# STM32H755_CM7 register map
File version: 2.6
CPU: CM7 r0p1, little endian, MPU, FPU, 4 interrupt priority bits
Registers are 32-bit, read-write, reset 0x0 unless marked. A register's access mark holds for its fields unless they carry their own. Offsets are from the block's base; [hi:lo] are bit positions; {n}, {i} and the like mark numbered series; 'fields as' and 'values as' point back to an identical list.

## ADC3_Common — Analog-to-Digital Converter
Base 0x58026300
Same registers: ADC12_Common 0x40022300
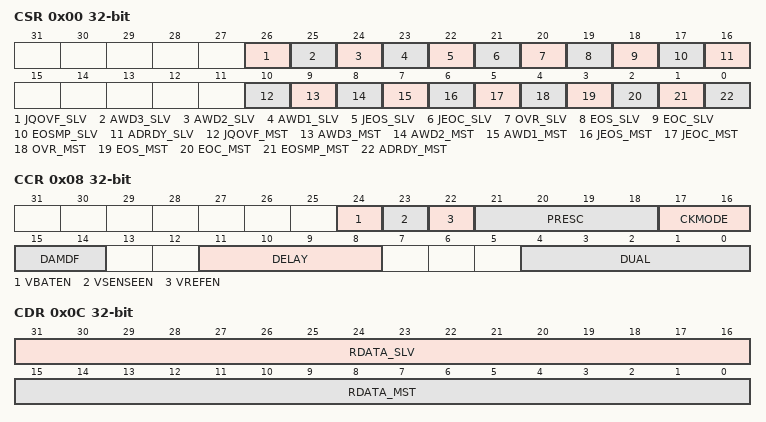
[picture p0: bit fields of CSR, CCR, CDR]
0x00 CSR ro — ADC Common status register
  [26] JQOVF_SLV — Injected Context Queue Overflow flag of the slave ADC
  [25] AWD3_SLV — Analog watchdog 3 flag of the slave ADC
  [24] AWD2_SLV — Analog watchdog 2 flag of the slave ADC
  [23] AWD1_SLV — Analog watchdog 1 flag of the slave ADC
  [22] JEOS_SLV — End of injected sequence flag of the slave ADC
  [21] JEOC_SLV — End of injected conversion flag of the slave ADC
  [20] OVR_SLV — Overrun flag of the slave ADC
  [19] EOS_SLV — End of regular sequence flag of the slave ADC
  [18] EOC_SLV — End of regular conversion of the slave ADC
  [17] EOSMP_SLV — End of Sampling phase flag of the slave ADC
  [16] ADRDY_SLV — Slave ADC ready
  [10] JQOVF_MST — Injected Context Queue Overflow flag of the master ADC
  [9] AWD3_MST — Analog watchdog 3 flag of the master ADC
  [8] AWD2_MST — Analog watchdog 2 flag of the master ADC
  [7] AWD1_MST — Analog watchdog 1 flag of the master ADC
  [6] JEOS_MST — End of injected sequence flag of the master ADC
  [5] JEOC_MST — End of injected conversion flag of the master ADC
  [4] OVR_MST — Overrun flag of the master ADC
  [3] EOS_MST — End of regular sequence flag of the master ADC
  [2] EOC_MST — End of regular conversion of the master ADC
  [1] EOSMP_MST — End of Sampling phase flag of the master ADC
  [0] ADRDY_MST — Master ADC ready
0x08 CCR — ADC common control register
  [24] VBATEN — VBAT enable
  [23] VSENSEEN — Temperature sensor enable
  [22] VREFEN — VREFINT enable
  [21:18] PRESC — ADC prescaler
  [17:16] CKMODE — ADC clock mode
  [15:14] DAMDF — Dual ADC Mode Data Format
  [11:8] DELAY — Delay between 2 sampling phases
  [4:0] DUAL — Dual ADC mode selection
0x0C CDR ro — ADC common regular data register for dual and triple modes
  [31:16] RDATA_SLV — Regular data of the slave ADC
  [15:0] RDATA_MST — Regular data of the master ADC
0x10 CDR2 ro — ADC x common regular data register for 32-bit dual mode
  [31:0] RDATA_ALT — Regular data of the master/slave alternated ADCs

## DMAMUX1 — DMAMUX
Base 0x40020800
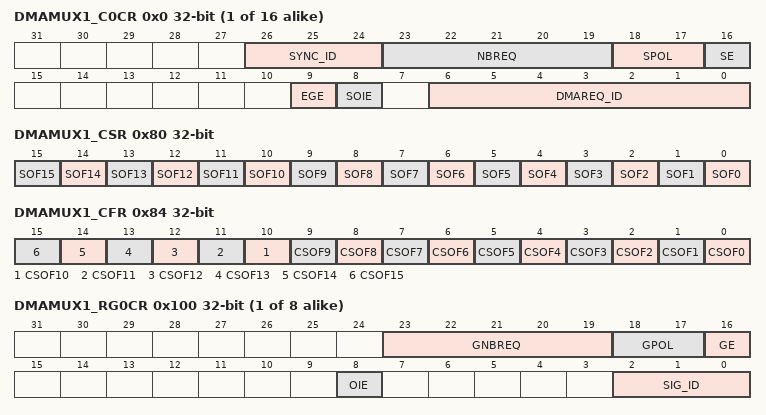
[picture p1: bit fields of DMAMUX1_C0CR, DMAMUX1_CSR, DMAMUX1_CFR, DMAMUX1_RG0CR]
{0x0+4i} DMAMUX1_C{i}CR (i=0..15)
  [26:24] SYNC_ID — Synchronization identification
  [23:19] NBREQ — Number of DMA requests minus 1 to forward
  [18:17] SPOL — Synchronization polarity
    0=No event, i; 1=Rising edge; 2=Falling edge; 3=Rising and falling edges
  [16] SE — Synchronization enable
    0=Synchronization disabled; 1=Synchronization enabled
  [9] EGE — Event generation enable
    0=Event generation disabled; 1=Event generation enabled
  [8] SOIE — Synchronization overrun interrupt enable
    0=Interrupt disabled; 1=Interrupt enabled
  [6:0] DMAREQ_ID — DMA request identification
0x80 DMAMUX1_CSR ro
  [n] SOF{n} (n=0..15) — Synchronization overrun event flag
0x84 DMAMUX1_CFR
  [n] CSOF{n} wo (n=0..15) — Clear synchronization overrun event flag
{0x100+4i} DMAMUX1_RG{i}CR (i=0..7)
  [23:19] GNBREQ — Number of DMA requests to be generated (minus 1)
  [18:17] GPOL — DMA request generator trigger polarity
    values as DMAMUX1_C0CR.SPOL
  [16] GE — DMA request generator channel x enable
    0=DMA request generator channel x disabled; 1=DMA request generator channel x enabled
  [8] OIE — Trigger overrun interrupt enable
    0=Interrupt on a trigger overrun event occurrence is disabled; 1=Interrupt on a trigger overrun event occurrence is enabled
  [2:0] SIG_ID — Signal identification
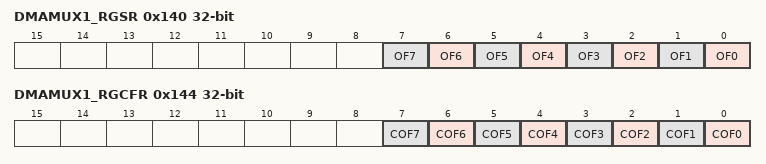
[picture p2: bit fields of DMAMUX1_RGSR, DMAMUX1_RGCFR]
0x140 DMAMUX1_RGSR ro
  [n] OF{n} (n=0..7) — [:0]: Trigger overrun event flag
0x144 DMAMUX1_RGCFR
  [n] COF{n} wo (n=0..7) — Clear trigger overrun event flag

## CRC — Cryptographic processor
Base 0x58024C00
0x00 DR reset 0xFFFFFFFF — Data register
  [31:0] DR — Data Register
0x04 IDR — Independent Data register
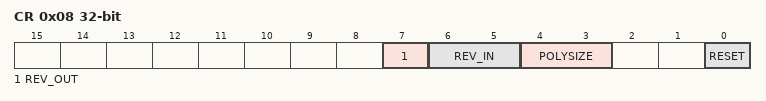
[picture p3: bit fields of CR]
0x08 CR — Control register
  [7] REV_OUT — Reverse output data
  [6:5] REV_IN — Reverse input data
  [4:3] POLYSIZE — Polynomial size
  [0] RESET — RESET bit
0x10 INIT reset 0xFFFFFFFF — Initial CRC value
  [31:0] CRC_INIT — Programmable initial CRC value
0x14 POL reset 0x4C11DB7 — CRC polynomial
  [31:0] POL — Programmable polynomial

## Notices in the file
Copyright (c) 2025 STMicroelectronics.
SPDX-License-Identifier: Apache-2.0
Licensed under the Apache License, Version 2.0 (the "License");
you may not use this file except in compliance with the License.
You may obtain a copy of the License at
http://www.apache.org/licenses/LICENSE-2.0
Unless required by applicable law or agreed to in writing, software
distributed under the License is distributed on an "AS IS" BASIS,
WITHOUT WARRANTIES OR CONDITIONS OF ANY KIND, either express or implied.
See the License for the specific language governing permissions and
limitations under the License.
